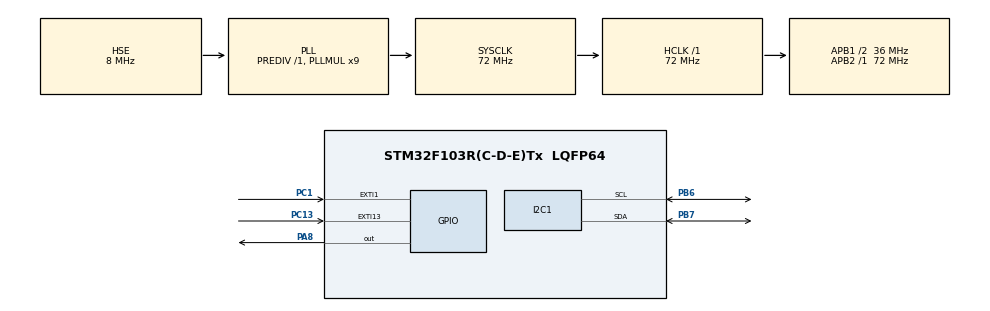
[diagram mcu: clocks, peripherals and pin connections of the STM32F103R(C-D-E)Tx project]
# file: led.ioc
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Mcu.Family=STM32F1
Mcu.Name=STM32F103R(C-D-E)Tx
Mcu.Package=LQFP64
NVIC.EXTI15_10_IRQn=true\:2\:0\:true\:false\:true\:true\:true\:true
NVIC.EXTI1_IRQn=true\:2\:0\:true\:false\:true\:true\:true\:true
NVIC.I2C1_ER_IRQn=true\:0\:0\:false\:false\:true\:true\:true\:true
NVIC.I2C1_EV_IRQn=true\:0\:0\:false\:false\:true\:true\:true\:true
NVIC.PriorityGroup=NVIC_PRIORITYGROUP_4
NVIC.TIM1_UP_IRQn=true\:0\:0\:false\:false\:true\:true\:true\:true
PA13.Mode=Serial_Wire
PA13.Signal=SYS_JTMS-SWDIO
PA14.Mode=Serial_Wire
PA14.Signal=SYS_JTCK-SWCLK
PA8.GPIO_ModeDefaultOutputPP=GPIO_MODE_OUTPUT_PP
PA8.GPIO_PuPd=GPIO_NOPULL
PA8.PinState=GPIO_PIN_RESET
PA8.Signal=GPIO_Output
PB6.GPIO_Mode=GPIO_MODE_AF_OD
PB6.Mode=I2C
PB6.Signal=I2C1_SCL
PB7.Mode=I2C
PB7.Signal=I2C1_SDA
PC1.GPIO_ModeDefaultEXTI=GPIO_MODE_IT_FALLING
PC1.Signal=GPXTI1
PC13-TAMPER-RTC.GPIO_ModeDefaultEXTI=GPIO_MODE_IT_FALLING
PC13-TAMPER-RTC.Signal=GPXTI13
PD0-OSC_IN.Mode=HSE-External-Oscillator
PD0-OSC_IN.Signal=RCC_OSC_IN
PD1-OSC_OUT.Mode=HSE-External-Oscillator
PD1-OSC_OUT.Signal=RCC_OSC_OUT
ProjectManager.HeapSize=0x200
ProjectManager.StackSize=0x400
ProjectManager.TargetToolchain=MDK-ARM V5.32
RCC.AHBFreq_Value=72000000
RCC.APB1CLKDivider=RCC_HCLK_DIV2
RCC.APB1Freq_Value=36000000
RCC.APB1TimFreq_Value=72000000
RCC.APB2Freq_Value=72000000
RCC.APB2TimFreq_Value=72000000
RCC.HCLKFreq_Value=72000000
RCC.PLLMUL=RCC_PLL_MUL9
RCC.PLLSourceVirtual=RCC_PLLSOURCE_HSE
RCC.SYSCLKFreq_VALUE=72000000
RCC.SYSCLKSource=RCC_SYSCLKSOURCE_PLLCLK
RCC.USBFreq_Value=72000000
TIM1.Period=1000 - 1
TIM1.Prescaler=80 - 1
VP_TIM1_VS_ClockSourceINT.Mode=Internal
board=custom

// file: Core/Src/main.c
/* USER CODE BEGIN Header */
/**
  ******************************************************************************
  * @file           : main.c
  * @brief          : Main program body
  ******************************************************************************
  * @attention
  *
  * Copyright (c) 2023 STMicroelectronics.
  * All rights reserved.
  *
  * This software is licensed under terms that can be found in the LICENSE file
  * in the root directory of this software component.
  * If no LICENSE file comes with this software, it is provided AS-IS.
  *
  ******************************************************************************
  */
/* USER CODE END Header */
#include "main.h"
#include "i2c.h"
#include "tim.h"
#include "gpio.h"

#include "test.h"
#include "stm32_u8g2.h"
/* USER CODE BEGIN Includes */

char ui_list = 0;//�б�λ��ȷ��
/* USER CODE END Includes */

void SystemClock_Config(void);

void HAL_GPIO_EXTI_Callback(uint16_t GPIO_Pin)
{
	if(HAL_GPIO_ReadPin(GPIOC,GPIO_PIN_13) == 0)
	{

		up_key();
	}

	else if(HAL_GPIO_ReadPin(GPIOC,GPIO_PIN_1) == 0)
	{
//		HAL_GPIO_WritePin(GPIOA,GPIO_PIN_8,1 - HAL_GPIO_ReadPin(GPIOA,GPIO_PIN_8));
		down_key();
	}
}

int main(void)
{

  /* MCU Configuration--------------------------------------------------------*/

  /* Reset of all peripherals, Initializes the Flash interface and the Systick. */
  HAL_Init();

  /* Configure the system clock */
  SystemClock_Config();

  /* Initialize all configured peripherals */
  MX_GPIO_Init();
  MX_I2C1_Init();
  MX_TIM1_Init();
  /* USER CODE BEGIN 2 */
	u8g2_t u8g2;
	u8g2Init(&u8g2);
	u8g2_FirstPage(&u8g2);
  /* USER CODE END 2 */
	u8g2Dra_init(&u8g2);
  /* Infinite loop */
  while (1)
  {

  }
}

void SystemClock_Config(void)
{
  RCC_OscInitTypeDef RCC_OscInitStruct = {0};
  RCC_ClkInitTypeDef RCC_ClkInitStruct = {0};

  /** Initializes the RCC Oscillators according to the specified parameters
  * in the RCC_OscInitTypeDef structure.
  */
  RCC_OscInitStruct.OscillatorType = RCC_OSCILLATORTYPE_HSE;
  RCC_OscInitStruct.HSEState = RCC_HSE_ON;
  RCC_OscInitStruct.HSEPredivValue = RCC_HSE_PREDIV_DIV1;
  RCC_OscInitStruct.HSIState = RCC_HSI_ON;
  RCC_OscInitStruct.PLL.PLLState = RCC_PLL_ON;
  RCC_OscInitStruct.PLL.PLLSource = RCC_PLLSOURCE_HSE;
  RCC_OscInitStruct.PLL.PLLMUL = RCC_PLL_MUL9;
  if (HAL_RCC_OscConfig(&RCC_OscInitStruct) != HAL_OK)
  {
    Error_Handler();
  }

  /** Initializes the CPU, AHB and APB buses clocks
  */
  RCC_ClkInitStruct.ClockType = RCC_CLOCKTYPE_HCLK|RCC_CLOCKTYPE_SYSCLK
                              |RCC_CLOCKTYPE_PCLK1|RCC_CLOCKTYPE_PCLK2;
  RCC_ClkInitStruct.SYSCLKSource = RCC_SYSCLKSOURCE_PLLCLK;
  RCC_ClkInitStruct.AHBCLKDivider = RCC_SYSCLK_DIV1;
  RCC_ClkInitStruct.APB1CLKDivider = RCC_HCLK_DIV2;
  RCC_ClkInitStruct.APB2CLKDivider = RCC_HCLK_DIV1;

  if (HAL_RCC_ClockConfig(&RCC_ClkInitStruct, FLASH_LATENCY_2) != HAL_OK)
  {
    Error_Handler();
  }
}

void Error_Handler(void)
{
  __disable_irq();
  while (1)
  {
  }
}
